# max32650 register map
Vendor: Maxim-Integrated; Series: ARMCM4; File version: 1.1
CPU: CM4 r2p1, little endian, MPU, FPU, 3 interrupt priority bits
Registers are 32-bit, read-write, reset 0x0 unless marked. A register's access mark holds for its fields unless they carry their own. Offsets are from the block's base; [hi:lo] are bit positions; {n}, {i} and the like mark numbered series.

## ADC — 10-bit Analog to Digital Converter
Base 0x40034000
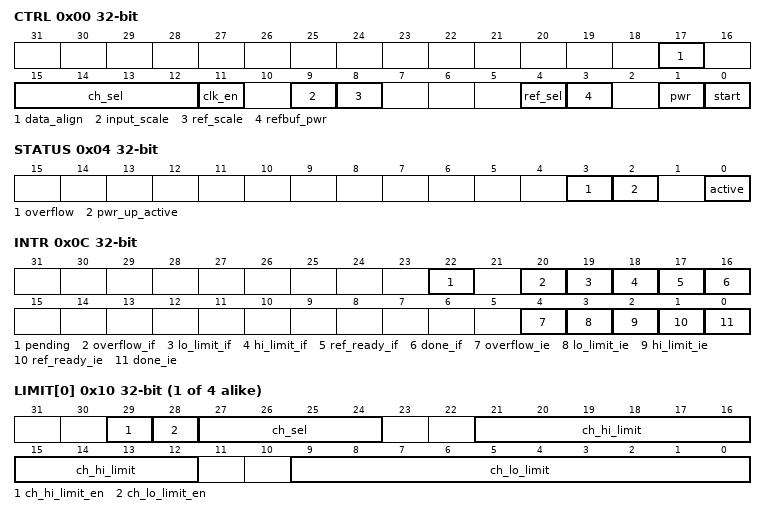
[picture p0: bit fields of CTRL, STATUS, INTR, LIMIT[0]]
0x00 CTRL — ADC Control
  [17] data_align — ADC Data Alignment Select
    0=lsb_justified; 1=msb_justified
  [15:12] ch_sel — ADC Channel Select
    {v}=ain{v} (v=0..3); 4=ain0_div5; 5=ain1_div5; 6=vddb_div4; 7=vdda; 8=vcore; 9=vrtc_div2; 10=rsv_0xa; 11=vddio_div4; 12=vddioh_div4
  [11] clk_en — ADC Clock Enable
    0=dis; 1=en
  [9] input_scale — ADC Scale
    0=div1; 1=div2
  [8] ref_scale — ADC Reference Scale
    0=div1; 1=div2
  [4] ref_sel — ADC Reference Select
    0=bandgap; 1=vdd_div2
  [3] refbuf_pwr — ADC Reference Buffer Power Up
    0=refbuf_off; 1=refbuf_on
  [1] pwr — ADC Power Up
    0=adc_off; 1=adc_on
  [0] start — Start ADC Conversion
    0=inactive; 1=start
0x04 STATUS — ADC Status
  [3] overflow ro — ADC Overflow
    0=underflow; 1=overflow
  [2] pwr_up_active ro — AFE Power Up Delay Active
    0=no_delay; 1=delay_active
  [0] active ro — ADC Conversion In Progress
    0=idle; 1=active
0x08 DATA — ADC Output Data
  [15:0] data ro — ADC Converted Sample Data Output
0x0C INTR — ADC Interrupt Control Register
  [22] pending ro — ADC Interrupt Pending Status
    0=no_int; 1=int_pending
  [20] overflow_if write-1-clears — ADC Overflow Interrupt Flag
    0=inactive; 1=active
  [19] lo_limit_if write-1-clears — ADC Lo Limit Monitor Interrupt Flag
    0=inactive; 1=active
  [18] hi_limit_if write-1-clears — ADC Hi Limit Monitor Interrupt Flag
    0=inactive; 1=active
  [17] ref_ready_if write-1-clears — ADC Reference Ready Interrupt Flag
    0=inactive; 1=active
  [16] done_if write-1-clears — ADC Done Interrupt Flag
    0=inactive; 1=active
  [4] overflow_ie — ADC Overflow Interrupt Enable
    0=dis; 1=en
  [3] lo_limit_ie — ADC Lo Limit Monitor Interrupt Enable
    0=dis; 1=en
  [2] hi_limit_ie — ADC Hi Limit Monitor Interrupt Enable
    0=dis; 1=en
  [1] ref_ready_ie — ADC Reference Ready Interrupt Enable
    0=dis; 1=en
  [0] done_ie — ADC Done Interrupt Enable
    0=dis; 1=en
{0x10+4i} LIMIT[{i}] (i=0..3) — ADC Limit
  [29] ch_hi_limit_en — High Limit Monitoring Enable
    0=dis; 1=en
  [28] ch_lo_limit_en — Low Limit Monitoring Enable
    0=dis; 1=en
  [27:24] ch_sel — ADC Channel Select
    {v}=ain{v} (v=0..12)
  [21:12] ch_hi_limit — High Limit Threshold
  [9:0] ch_lo_limit — Low Limit Threshold

## AESKEYS — AES Key Registers.
Base 0x40005000
{0x0+4i} KEY0[{i}] (i=0..3) — AES Key 0.
{0x80+4i} KEY1[{i}] (i=0..3) — AES Key 1.
{0x100+4i} KEY2[{i}] (i=0..3) — AES Key 2.
{0x180+4i} KEY3[{i}] (i=0..3) — AES Key 3.

## EMCC — External Memory Cache Controller Registers.
Base 0x40033000
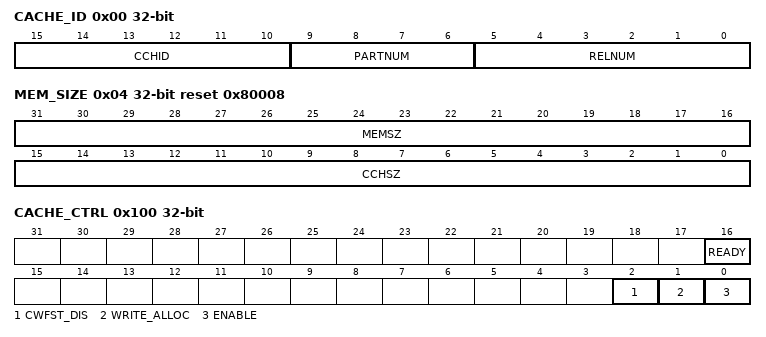
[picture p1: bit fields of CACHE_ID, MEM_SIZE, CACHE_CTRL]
0x00 CACHE_ID ro
  [15:10] CCHID — Cache ID. This field reflects the value of the C_ID_CACHEID configuration parameter.
  [9:6] PARTNUM — Part Number. This field reflects the value of C_ID_PART_NUMBER configuration parameter.
  [5:0] RELNUM — Release Number. Identifies the RTL release version.
0x04 MEM_SIZE ro reset 0x80008 — Memory Configuration Register.
  [31:16] MEMSZ — Main Memory Size. Indicates the total size, in units of 128 Kbytes, of code memory accessible to the cache controller.
  [15:0] CCHSZ — Cache Size. Indicates total size in Kbytes of cache.
0x100 CACHE_CTRL — Cache Control and Status Register.
  [16] READY — Cache Ready flag. Cleared by hardware when at any time the cache as a whole is invalidated (including a system reset). When this bit is 0, the cache is effectively in bypass mode (instruction fetches will come from main memory or from the line fill buffer). Set by hardware when the invalidate operation is complete and the cache is ready.
    0=notReady; 1=ready
  [2] CWFST_DIS — Critical word first and streaming disable. This bit only writeable while the cache is disabled.
    1=dis (Critical word first and streaming disabled.); 0=en (Critical word first and streaming enabled.)
  [1] WRITE_ALLOC — Write Allocate Enable. This bit only writable while the cache is disabled.
    0=dis (Write-no-allocate.); 1=en (Write-allocate enabled.)
  [0] ENABLE — Cache Enable. Controls whether the cache is bypassed or is in use. Changing the state of this bit will cause the instruction cache to be flushed and its contents invalidated.
    0=dis (Cache Bypassed. Instruction data is stored in the line fill buffer but is not written to main cache memory array.); 1=en (Cache Enabled.)
0x700 INVALIDATE — Invalidate All Cache Contents. Any time this register location is written (regardless of the data value), the cache controller immediately begins invalidating the entire contents of the cache memory. The cache will be in bypass mode until the invalidate operation is complete. System software can examine the Cache Ready bit (CACHE_CTRL.CACHE_RDY) to determine when the invalidate operation is complete. Note that it is not necessary to disable the cache controller prior to beginning this operation. Reads from this register always return 0.
  [31:0] IA — Invalidate all cache contents.
